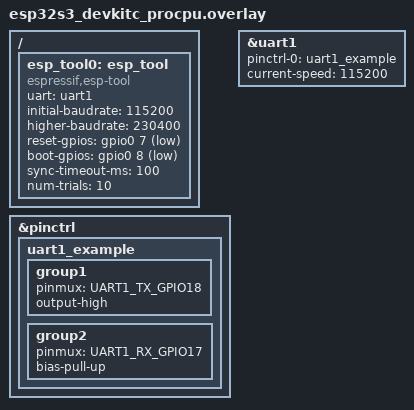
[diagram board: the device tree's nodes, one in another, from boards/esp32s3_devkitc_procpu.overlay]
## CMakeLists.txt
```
# SPDX-License-Identifier: Apache-2.0

cmake_minimum_required(VERSION 3.20.0)

find_package(Zephyr REQUIRED HINTS $ENV{ZEPHYR_BASE})
project(esp_tool_demo)

target_sources(app PRIVATE src/main.c)

if (CONFIG_ESP_TOOL_SHELL)
  target_sources(app PRIVATE src/shell.c)
endif()

if (CONFIG_ESP_TOOL_FW_ARRAYS)
  create_resources(${CMAKE_CURRENT_SOURCE_DIR}/target-firmware
                   ${CMAKE_CURRENT_SOURCE_DIR}/res/target_firmware_data.c)
  target_sources(app PRIVATE res/target_firmware_data.c)
endif()
```

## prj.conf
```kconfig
CONFIG_ESP_SERIAL_FLASHER=y
CONFIG_GPIO=y
CONFIG_SERIAL=y
CONFIG_CONSOLE=y
CONFIG_CONSOLE_GETCHAR=y
CONFIG_SHELL=y
CONFIG_ESP_TOOL=y
CONFIG_ESP_TOOL_SHELL=y
```

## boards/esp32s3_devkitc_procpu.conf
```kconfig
CONFIG_SERIAL_FLASHER_BOOT_INVERT=y
CONFIG_SERIAL_FLASHER_RESET_INVERT=y
CONFIG_SERIAL_FLASHER_DEBUG_TRACE=n
CONFIG_SERIAL_FLASHER_INTERFACE_UART=y
```

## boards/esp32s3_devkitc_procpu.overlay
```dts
/
{
	esp_tool0: esp_tool {
		compatible = "espressif,esp-tool";
		uart = <&uart1>;
		initial-baudrate = <115200>;
		higher-baudrate = <230400>;
		reset-gpios = <&gpio0 7 (GPIO_ACTIVE_LOW | GPIO_PULL_UP)>;
		boot-gpios = <&gpio0 8 (GPIO_ACTIVE_LOW | GPIO_PULL_UP)>;
		//reset-gpios = <&gpio0 7 (GPIO_ACTIVE_LOW)>; // | GPIO_PULL_UP)>;
		//boot-gpios = <&gpio0 8 (GPIO_ACTIVE_LOW)>; // | GPIO_PULL_UP)>;
		//enable-gpios = <&gpio0 7 (GPIO_ACTIVE_HIGH)>; // | GPIO_PULL_UP)>;
		sync-timeout-ms = <100>;
		num-trials = <10>;
	};
};

/*
&uart1_default {
	group1 {
		pinmux = <UART1_TX_GPIO18>;
		output-high;
	};

	group2 {
		pinmux = <UART1_RX_GPIO17>;
		bias-pull-up;
	};
};
*/

&pinctrl {
	uart1_example: uart1_example {
		group1 {
			pinmux = <UART1_TX_GPIO18>;
			output-high;
		};

		group2 {
			pinmux = <UART1_RX_GPIO17>;
			bias-pull-up;
		};
	};
};

&uart1 {
	pinctrl-0 = <&uart1_example>;
	pinctrl-names = "default";
	current-speed = <115200>;
	status = "okay";
};

&esp_tool0 {
	status = "okay";
};
```

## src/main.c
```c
/*
 * Copyright (c) 2025 Espressif Systems (Shanghai) Co., Ltd.
 *
 * SPDX-License-Identifier: Apache-2.0
 */

#include <zephyr/kernel.h>
#include <zephyr/sys/printk.h>
#include <zephyr/drivers/misc/esp_tool/esp_tool.h>
#include <zephyr/device.h>

/* local */
//#include "hexdump.h"

static const struct device *esp = DEVICE_DT_GET(DT_INST(0, espressif_esp_tool));
//static uint8_t buf[128];

int main(void)
{
	int ret;
	uint32_t flash_size, chip_id;
	uint32_t offset;
	char *name;

	ret = device_is_ready(esp);
	if (ret == 0) {
		printk("ESP device is not ready (err=%d).\n", ret);
		return -1;
	}
	printk("ESP device is ready (ret=%d).\n", ret);

#if 0
	ret = esp_tool_connect_stub(esp, 0);
	if (ret) {
		printk("Could not open esp device\n");
		return -1;
	}
	printk("ESP device connected\n");

	ret = esp_tool_get_target(esp, &chip_id);
	if (ret) {
		printk("Target detection failed!\n");
		return -1;
	}
	printk("Target chip id is %x\n", chip_id);

	ret = esp_tool_get_target_name(esp, &name);
	if (ret) {
		printk("Target name detection failed!\n");
		return -1;
	}
	printk("Target name %s\n", name);

	ret = esp_tool_flash_detect_size(esp, &flash_size);
	if (ret) {
		printk("Could not detected flash size\n");
		return -1;
	}
	printk("Detected flash size is %d MB (%d Bytes)\n",
		flash_size/1024/1024, flash_size);

	if (esp_tool_get_boot_offset(esp, &offset)) {
		printk("boot offset failed\n");
		return -1;
	}
	printk("Target chip boot offset is 0x%x\n", offset);

	ret = esp_tool_flash_read(esp, offset, buf, sizeof(buf));
	if (ret) {
		printk("flash read ret=%d\n", ret);
		return -1;
	}

	hexdump("0x0", buf, sizeof(buf));

	if (buf[0] == 0xe9) {
		printk("Boot vector installed\n");
	} else {
		printk("Target chip not bootable!\n");
	}

	printk("Resetting target...");

	ret = esp_tool_reset_target(esp);
	if (ret) {
		printk(" Failed\n");
		return -1;
	}
	printk("OK\n\n");
#endif

	return 0;
}
```
